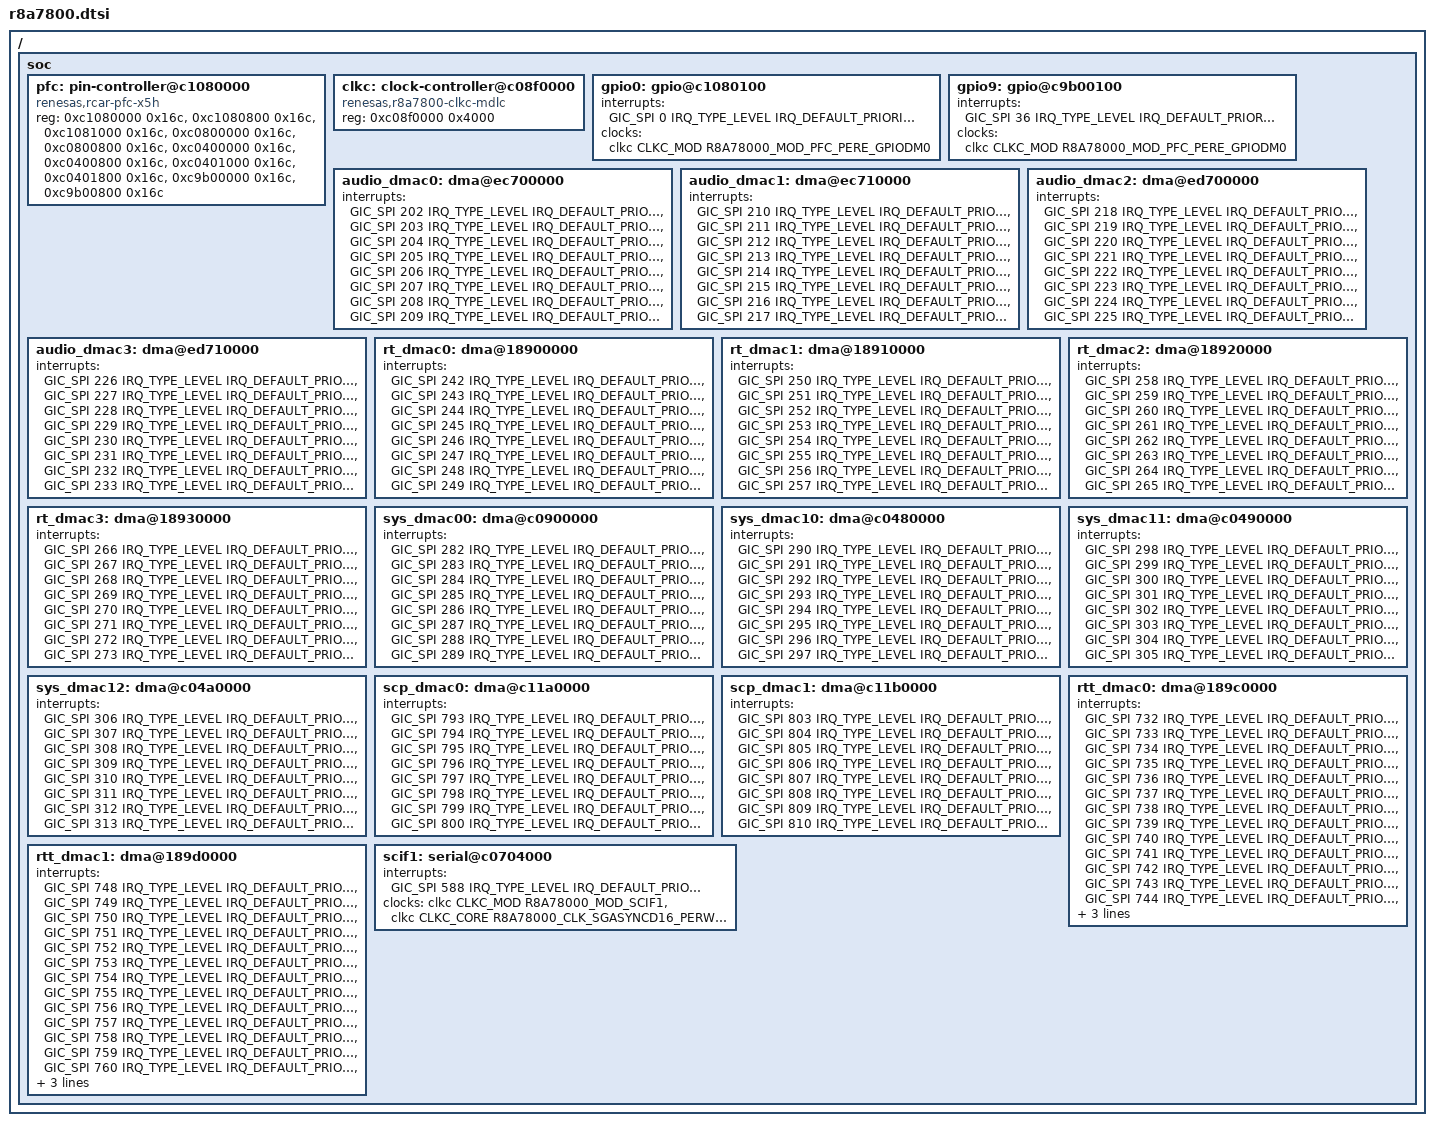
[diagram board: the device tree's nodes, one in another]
/*
 * Copyright (c) 2026 Renesas Electronics Corporation
 *
 * SPDX-License-Identifier: Apache-2.0
 */

#include <renesas/rcar/gen5/rcar_gen5_cr52.dtsi>
#include <zephyr/dt-bindings/clock/r8a7800_clkc_mdlc.h>

/ {
	soc {
		pfc: pin-controller@c1080000 {
			compatible = "renesas,rcar-pfc-x5h";
			reg = <0xc1080000 0x16c>, <0xc1080800 0x16c>,
			      <0xc1081000 0x16c>, <0xc0800000 0x16c>,
			      <0xc0800800 0x16c>, <0xc0400000 0x16c>,
			      <0xc0400800 0x16c>, <0xc0401000 0x16c>,
			      <0xc0401800 0x16c>, <0xc9b00000 0x16c>,
			      <0xc9b00800 0x16c>;
		};

		clkc: clock-controller@c08f0000 {
			compatible = "renesas,r8a7800-clkc-mdlc";
			reg = <0xc08f0000 0x4000>;
			#clock-cells = <2>;
		};

		gpio0: gpio@c1080100 {
			interrupts = <GIC_SPI 0 IRQ_TYPE_LEVEL IRQ_DEFAULT_PRIORITY>;
			clocks = <&clkc CLKC_MOD R8A78000_MOD_PFC_PERE_GPIODM0>;
		};

		gpio9: gpio@c9b00100 {
			interrupts = <GIC_SPI 36 IRQ_TYPE_LEVEL IRQ_DEFAULT_PRIORITY>;
			clocks = <&clkc CLKC_MOD R8A78000_MOD_PFC_PERE_GPIODM0>;
		};

		audio_dmac0: dma@ec700000 {
			interrupts = <GIC_SPI 202 IRQ_TYPE_LEVEL IRQ_DEFAULT_PRIORITY>,
				     <GIC_SPI 203 IRQ_TYPE_LEVEL IRQ_DEFAULT_PRIORITY>,
				     <GIC_SPI 204 IRQ_TYPE_LEVEL IRQ_DEFAULT_PRIORITY>,
				     <GIC_SPI 205 IRQ_TYPE_LEVEL IRQ_DEFAULT_PRIORITY>,
				     <GIC_SPI 206 IRQ_TYPE_LEVEL IRQ_DEFAULT_PRIORITY>,
				     <GIC_SPI 207 IRQ_TYPE_LEVEL IRQ_DEFAULT_PRIORITY>,
				     <GIC_SPI 208 IRQ_TYPE_LEVEL IRQ_DEFAULT_PRIORITY>,
				     <GIC_SPI 209 IRQ_TYPE_LEVEL IRQ_DEFAULT_PRIORITY>;
			interrupt-names = "ch0", "ch2", "ch4", "ch6",
					  "ch8", "ch10", "ch12", "ch14";
		};

		audio_dmac1: dma@ec710000 {
			interrupts = <GIC_SPI 210 IRQ_TYPE_LEVEL IRQ_DEFAULT_PRIORITY>,
				     <GIC_SPI 211 IRQ_TYPE_LEVEL IRQ_DEFAULT_PRIORITY>,
				     <GIC_SPI 212 IRQ_TYPE_LEVEL IRQ_DEFAULT_PRIORITY>,
				     <GIC_SPI 213 IRQ_TYPE_LEVEL IRQ_DEFAULT_PRIORITY>,
				     <GIC_SPI 214 IRQ_TYPE_LEVEL IRQ_DEFAULT_PRIORITY>,
				     <GIC_SPI 215 IRQ_TYPE_LEVEL IRQ_DEFAULT_PRIORITY>,
				     <GIC_SPI 216 IRQ_TYPE_LEVEL IRQ_DEFAULT_PRIORITY>,
				     <GIC_SPI 217 IRQ_TYPE_LEVEL IRQ_DEFAULT_PRIORITY>;
			interrupt-names = "ch0", "ch2", "ch4", "ch6",
					  "ch8", "ch10", "ch12", "ch14";
		};

		audio_dmac2: dma@ed700000 {
			interrupts = <GIC_SPI 218 IRQ_TYPE_LEVEL IRQ_DEFAULT_PRIORITY>,
				     <GIC_SPI 219 IRQ_TYPE_LEVEL IRQ_DEFAULT_PRIORITY>,
				     <GIC_SPI 220 IRQ_TYPE_LEVEL IRQ_DEFAULT_PRIORITY>,
				     <GIC_SPI 221 IRQ_TYPE_LEVEL IRQ_DEFAULT_PRIORITY>,
				     <GIC_SPI 222 IRQ_TYPE_LEVEL IRQ_DEFAULT_PRIORITY>,
				     <GIC_SPI 223 IRQ_TYPE_LEVEL IRQ_DEFAULT_PRIORITY>,
				     <GIC_SPI 224 IRQ_TYPE_LEVEL IRQ_DEFAULT_PRIORITY>,
				     <GIC_SPI 225 IRQ_TYPE_LEVEL IRQ_DEFAULT_PRIORITY>;
			interrupt-names = "ch0", "ch2", "ch4", "ch6",
					  "ch8", "ch10", "ch12", "ch14";
		};

		audio_dmac3: dma@ed710000 {
			interrupts = <GIC_SPI 226 IRQ_TYPE_LEVEL IRQ_DEFAULT_PRIORITY>,
				     <GIC_SPI 227 IRQ_TYPE_LEVEL IRQ_DEFAULT_PRIORITY>,
				     <GIC_SPI 228 IRQ_TYPE_LEVEL IRQ_DEFAULT_PRIORITY>,
				     <GIC_SPI 229 IRQ_TYPE_LEVEL IRQ_DEFAULT_PRIORITY>,
				     <GIC_SPI 230 IRQ_TYPE_LEVEL IRQ_DEFAULT_PRIORITY>,
				     <GIC_SPI 231 IRQ_TYPE_LEVEL IRQ_DEFAULT_PRIORITY>,
				     <GIC_SPI 232 IRQ_TYPE_LEVEL IRQ_DEFAULT_PRIORITY>,
				     <GIC_SPI 233 IRQ_TYPE_LEVEL IRQ_DEFAULT_PRIORITY>;
			interrupt-names = "ch0", "ch2", "ch4", "ch6",
					  "ch8", "ch10", "ch12", "ch14";
		};

		rt_dmac0: dma@18900000 {
			interrupts = <GIC_SPI 242 IRQ_TYPE_LEVEL IRQ_DEFAULT_PRIORITY>,
				     <GIC_SPI 243 IRQ_TYPE_LEVEL IRQ_DEFAULT_PRIORITY>,
				     <GIC_SPI 244 IRQ_TYPE_LEVEL IRQ_DEFAULT_PRIORITY>,
				     <GIC_SPI 245 IRQ_TYPE_LEVEL IRQ_DEFAULT_PRIORITY>,
				     <GIC_SPI 246 IRQ_TYPE_LEVEL IRQ_DEFAULT_PRIORITY>,
				     <GIC_SPI 247 IRQ_TYPE_LEVEL IRQ_DEFAULT_PRIORITY>,
				     <GIC_SPI 248 IRQ_TYPE_LEVEL IRQ_DEFAULT_PRIORITY>,
				     <GIC_SPI 249 IRQ_TYPE_LEVEL IRQ_DEFAULT_PRIORITY>;
			interrupt-names = "ch0", "ch2", "ch4", "ch6",
					  "ch8", "ch10", "ch12", "ch14";
		};

		rt_dmac1: dma@18910000 {
			interrupts = <GIC_SPI 250 IRQ_TYPE_LEVEL IRQ_DEFAULT_PRIORITY>,
				     <GIC_SPI 251 IRQ_TYPE_LEVEL IRQ_DEFAULT_PRIORITY>,
				     <GIC_SPI 252 IRQ_TYPE_LEVEL IRQ_DEFAULT_PRIORITY>,
				     <GIC_SPI 253 IRQ_TYPE_LEVEL IRQ_DEFAULT_PRIORITY>,
				     <GIC_SPI 254 IRQ_TYPE_LEVEL IRQ_DEFAULT_PRIORITY>,
				     <GIC_SPI 255 IRQ_TYPE_LEVEL IRQ_DEFAULT_PRIORITY>,
				     <GIC_SPI 256 IRQ_TYPE_LEVEL IRQ_DEFAULT_PRIORITY>,
				     <GIC_SPI 257 IRQ_TYPE_LEVEL IRQ_DEFAULT_PRIORITY>;
			interrupt-names = "ch0", "ch2", "ch4", "ch6",
					  "ch8", "ch10", "ch12", "ch14";
		};

		rt_dmac2: dma@18920000 {
			interrupts = <GIC_SPI 258 IRQ_TYPE_LEVEL IRQ_DEFAULT_PRIORITY>,
				     <GIC_SPI 259 IRQ_TYPE_LEVEL IRQ_DEFAULT_PRIORITY>,
				     <GIC_SPI 260 IRQ_TYPE_LEVEL IRQ_DEFAULT_PRIORITY>,
				     <GIC_SPI 261 IRQ_TYPE_LEVEL IRQ_DEFAULT_PRIORITY>,
				     <GIC_SPI 262 IRQ_TYPE_LEVEL IRQ_DEFAULT_PRIORITY>,
				     <GIC_SPI 263 IRQ_TYPE_LEVEL IRQ_DEFAULT_PRIORITY>,
				     <GIC_SPI 264 IRQ_TYPE_LEVEL IRQ_DEFAULT_PRIORITY>,
				     <GIC_SPI 265 IRQ_TYPE_LEVEL IRQ_DEFAULT_PRIORITY>;
			interrupt-names = "ch0", "ch2", "ch4", "ch6",
					  "ch8", "ch10", "ch12", "ch14";
		};

		rt_dmac3: dma@18930000 {
			interrupts = <GIC_SPI 266 IRQ_TYPE_LEVEL IRQ_DEFAULT_PRIORITY>,
				     <GIC_SPI 267 IRQ_TYPE_LEVEL IRQ_DEFAULT_PRIORITY>,
				     <GIC_SPI 268 IRQ_TYPE_LEVEL IRQ_DEFAULT_PRIORITY>,
				     <GIC_SPI 269 IRQ_TYPE_LEVEL IRQ_DEFAULT_PRIORITY>,
				     <GIC_SPI 270 IRQ_TYPE_LEVEL IRQ_DEFAULT_PRIORITY>,
				     <GIC_SPI 271 IRQ_TYPE_LEVEL IRQ_DEFAULT_PRIORITY>,
				     <GIC_SPI 272 IRQ_TYPE_LEVEL IRQ_DEFAULT_PRIORITY>,
				     <GIC_SPI 273 IRQ_TYPE_LEVEL IRQ_DEFAULT_PRIORITY>;
			interrupt-names = "ch0", "ch2", "ch4", "ch6",
					  "ch8", "ch10", "ch12", "ch14";
		};

		sys_dmac00: dma@c0900000 {
			interrupts = <GIC_SPI 282 IRQ_TYPE_LEVEL IRQ_DEFAULT_PRIORITY>,
				     <GIC_SPI 283 IRQ_TYPE_LEVEL IRQ_DEFAULT_PRIORITY>,
				     <GIC_SPI 284 IRQ_TYPE_LEVEL IRQ_DEFAULT_PRIORITY>,
				     <GIC_SPI 285 IRQ_TYPE_LEVEL IRQ_DEFAULT_PRIORITY>,
				     <GIC_SPI 286 IRQ_TYPE_LEVEL IRQ_DEFAULT_PRIORITY>,
				     <GIC_SPI 287 IRQ_TYPE_LEVEL IRQ_DEFAULT_PRIORITY>,
				     <GIC_SPI 288 IRQ_TYPE_LEVEL IRQ_DEFAULT_PRIORITY>,
				     <GIC_SPI 289 IRQ_TYPE_LEVEL IRQ_DEFAULT_PRIORITY>;
			interrupt-names = "ch0", "ch2", "ch4", "ch6",
					  "ch8", "ch10", "ch12", "ch14";
		};

		sys_dmac10: dma@c0480000 {
			interrupts = <GIC_SPI 290 IRQ_TYPE_LEVEL IRQ_DEFAULT_PRIORITY>,
				     <GIC_SPI 291 IRQ_TYPE_LEVEL IRQ_DEFAULT_PRIORITY>,
				     <GIC_SPI 292 IRQ_TYPE_LEVEL IRQ_DEFAULT_PRIORITY>,
				     <GIC_SPI 293 IRQ_TYPE_LEVEL IRQ_DEFAULT_PRIORITY>,
				     <GIC_SPI 294 IRQ_TYPE_LEVEL IRQ_DEFAULT_PRIORITY>,
				     <GIC_SPI 295 IRQ_TYPE_LEVEL IRQ_DEFAULT_PRIORITY>,
				     <GIC_SPI 296 IRQ_TYPE_LEVEL IRQ_DEFAULT_PRIORITY>,
				     <GIC_SPI 297 IRQ_TYPE_LEVEL IRQ_DEFAULT_PRIORITY>;
			interrupt-names = "ch0", "ch2", "ch4", "ch6",
					  "ch8", "ch10", "ch12", "ch14";
		};

		sys_dmac11: dma@c0490000 {
			interrupts = <GIC_SPI 298 IRQ_TYPE_LEVEL IRQ_DEFAULT_PRIORITY>,
				     <GIC_SPI 299 IRQ_TYPE_LEVEL IRQ_DEFAULT_PRIORITY>,
				     <GIC_SPI 300 IRQ_TYPE_LEVEL IRQ_DEFAULT_PRIORITY>,
				     <GIC_SPI 301 IRQ_TYPE_LEVEL IRQ_DEFAULT_PRIORITY>,
				     <GIC_SPI 302 IRQ_TYPE_LEVEL IRQ_DEFAULT_PRIORITY>,
				     <GIC_SPI 303 IRQ_TYPE_LEVEL IRQ_DEFAULT_PRIORITY>,
				     <GIC_SPI 304 IRQ_TYPE_LEVEL IRQ_DEFAULT_PRIORITY>,
				     <GIC_SPI 305 IRQ_TYPE_LEVEL IRQ_DEFAULT_PRIORITY>;
			interrupt-names = "ch0", "ch2", "ch4", "ch6",
					  "ch8", "ch10", "ch12", "ch14";
		};

		sys_dmac12: dma@c04a0000 {
			interrupts = <GIC_SPI 306 IRQ_TYPE_LEVEL IRQ_DEFAULT_PRIORITY>,
				     <GIC_SPI 307 IRQ_TYPE_LEVEL IRQ_DEFAULT_PRIORITY>,
				     <GIC_SPI 308 IRQ_TYPE_LEVEL IRQ_DEFAULT_PRIORITY>,
				     <GIC_SPI 309 IRQ_TYPE_LEVEL IRQ_DEFAULT_PRIORITY>,
				     <GIC_SPI 310 IRQ_TYPE_LEVEL IRQ_DEFAULT_PRIORITY>,
				     <GIC_SPI 311 IRQ_TYPE_LEVEL IRQ_DEFAULT_PRIORITY>,
				     <GIC_SPI 312 IRQ_TYPE_LEVEL IRQ_DEFAULT_PRIORITY>,
				     <GIC_SPI 313 IRQ_TYPE_LEVEL IRQ_DEFAULT_PRIORITY>;
			interrupt-names = "ch0", "ch2", "ch4", "ch6",
					  "ch8", "ch10", "ch12", "ch14";
		};

		scp_dmac0: dma@c11a0000 {
			interrupts = <GIC_SPI 793 IRQ_TYPE_LEVEL IRQ_DEFAULT_PRIORITY>,
				     <GIC_SPI 794 IRQ_TYPE_LEVEL IRQ_DEFAULT_PRIORITY>,
				     <GIC_SPI 795 IRQ_TYPE_LEVEL IRQ_DEFAULT_PRIORITY>,
				     <GIC_SPI 796 IRQ_TYPE_LEVEL IRQ_DEFAULT_PRIORITY>,
				     <GIC_SPI 797 IRQ_TYPE_LEVEL IRQ_DEFAULT_PRIORITY>,
				     <GIC_SPI 798 IRQ_TYPE_LEVEL IRQ_DEFAULT_PRIORITY>,
				     <GIC_SPI 799 IRQ_TYPE_LEVEL IRQ_DEFAULT_PRIORITY>,
				     <GIC_SPI 800 IRQ_TYPE_LEVEL IRQ_DEFAULT_PRIORITY>;
			interrupt-names = "ch0", "ch2", "ch4", "ch6",
					  "ch8", "ch10", "ch12", "ch14";
		};

		scp_dmac1: dma@c11b0000 {
			interrupts = <GIC_SPI 803 IRQ_TYPE_LEVEL IRQ_DEFAULT_PRIORITY>,
				     <GIC_SPI 804 IRQ_TYPE_LEVEL IRQ_DEFAULT_PRIORITY>,
				     <GIC_SPI 805 IRQ_TYPE_LEVEL IRQ_DEFAULT_PRIORITY>,
				     <GIC_SPI 806 IRQ_TYPE_LEVEL IRQ_DEFAULT_PRIORITY>,
				     <GIC_SPI 807 IRQ_TYPE_LEVEL IRQ_DEFAULT_PRIORITY>,
				     <GIC_SPI 808 IRQ_TYPE_LEVEL IRQ_DEFAULT_PRIORITY>,
				     <GIC_SPI 809 IRQ_TYPE_LEVEL IRQ_DEFAULT_PRIORITY>,
				     <GIC_SPI 810 IRQ_TYPE_LEVEL IRQ_DEFAULT_PRIORITY>;
			interrupt-names = "ch0", "ch2", "ch4", "ch6",
					  "ch8", "ch10", "ch12", "ch14";
		};

		rtt_dmac0: dma@189c0000 {
			interrupts = <GIC_SPI 732 IRQ_TYPE_LEVEL IRQ_DEFAULT_PRIORITY>,
				     <GIC_SPI 733 IRQ_TYPE_LEVEL IRQ_DEFAULT_PRIORITY>,
				     <GIC_SPI 734 IRQ_TYPE_LEVEL IRQ_DEFAULT_PRIORITY>,
				     <GIC_SPI 735 IRQ_TYPE_LEVEL IRQ_DEFAULT_PRIORITY>,
				     <GIC_SPI 736 IRQ_TYPE_LEVEL IRQ_DEFAULT_PRIORITY>,
				     <GIC_SPI 737 IRQ_TYPE_LEVEL IRQ_DEFAULT_PRIORITY>,
				     <GIC_SPI 738 IRQ_TYPE_LEVEL IRQ_DEFAULT_PRIORITY>,
				     <GIC_SPI 739 IRQ_TYPE_LEVEL IRQ_DEFAULT_PRIORITY>,
				     <GIC_SPI 740 IRQ_TYPE_LEVEL IRQ_DEFAULT_PRIORITY>,
				     <GIC_SPI 741 IRQ_TYPE_LEVEL IRQ_DEFAULT_PRIORITY>,
				     <GIC_SPI 742 IRQ_TYPE_LEVEL IRQ_DEFAULT_PRIORITY>,
				     <GIC_SPI 743 IRQ_TYPE_LEVEL IRQ_DEFAULT_PRIORITY>,
				     <GIC_SPI 744 IRQ_TYPE_LEVEL IRQ_DEFAULT_PRIORITY>,
				     <GIC_SPI 745 IRQ_TYPE_LEVEL IRQ_DEFAULT_PRIORITY>,
				     <GIC_SPI 746 IRQ_TYPE_LEVEL IRQ_DEFAULT_PRIORITY>,
				     <GIC_SPI 747 IRQ_TYPE_LEVEL IRQ_DEFAULT_PRIORITY>;
			interrupt-names = "ch0", "ch1", "ch2", "ch3",
					  "ch4", "ch5", "ch6", "ch7",
					  "ch8", "ch9", "ch10", "ch11",
					  "ch12", "ch13", "ch14", "ch15";
		};

		rtt_dmac1: dma@189d0000 {
			interrupts = <GIC_SPI 748 IRQ_TYPE_LEVEL IRQ_DEFAULT_PRIORITY>,
				     <GIC_SPI 749 IRQ_TYPE_LEVEL IRQ_DEFAULT_PRIORITY>,
				     <GIC_SPI 750 IRQ_TYPE_LEVEL IRQ_DEFAULT_PRIORITY>,
				     <GIC_SPI 751 IRQ_TYPE_LEVEL IRQ_DEFAULT_PRIORITY>,
				     <GIC_SPI 752 IRQ_TYPE_LEVEL IRQ_DEFAULT_PRIORITY>,
				     <GIC_SPI 753 IRQ_TYPE_LEVEL IRQ_DEFAULT_PRIORITY>,
				     <GIC_SPI 754 IRQ_TYPE_LEVEL IRQ_DEFAULT_PRIORITY>,
				     <GIC_SPI 755 IRQ_TYPE_LEVEL IRQ_DEFAULT_PRIORITY>,
				     <GIC_SPI 756 IRQ_TYPE_LEVEL IRQ_DEFAULT_PRIORITY>,
				     <GIC_SPI 757 IRQ_TYPE_LEVEL IRQ_DEFAULT_PRIORITY>,
				     <GIC_SPI 758 IRQ_TYPE_LEVEL IRQ_DEFAULT_PRIORITY>,
				     <GIC_SPI 759 IRQ_TYPE_LEVEL IRQ_DEFAULT_PRIORITY>,
				     <GIC_SPI 760 IRQ_TYPE_LEVEL IRQ_DEFAULT_PRIORITY>,
				     <GIC_SPI 761 IRQ_TYPE_LEVEL IRQ_DEFAULT_PRIORITY>,
				     <GIC_SPI 762 IRQ_TYPE_LEVEL IRQ_DEFAULT_PRIORITY>,
				     <GIC_SPI 763 IRQ_TYPE_LEVEL IRQ_DEFAULT_PRIORITY>;
			interrupt-names = "ch0", "ch1", "ch2", "ch3",
					  "ch4", "ch5", "ch6", "ch7",
					  "ch8", "ch9", "ch10", "ch11",
					  "ch12", "ch13", "ch14", "ch15";
		};

		scif1: serial@c0704000 {
			interrupts = <GIC_SPI 588 IRQ_TYPE_LEVEL IRQ_DEFAULT_PRIORITY>;
			clocks = <&clkc CLKC_MOD R8A78000_MOD_SCIF1>,
				 <&clkc CLKC_CORE R8A78000_CLK_SGASYNCD16_PERW_BUS>;
		};
	};
};
